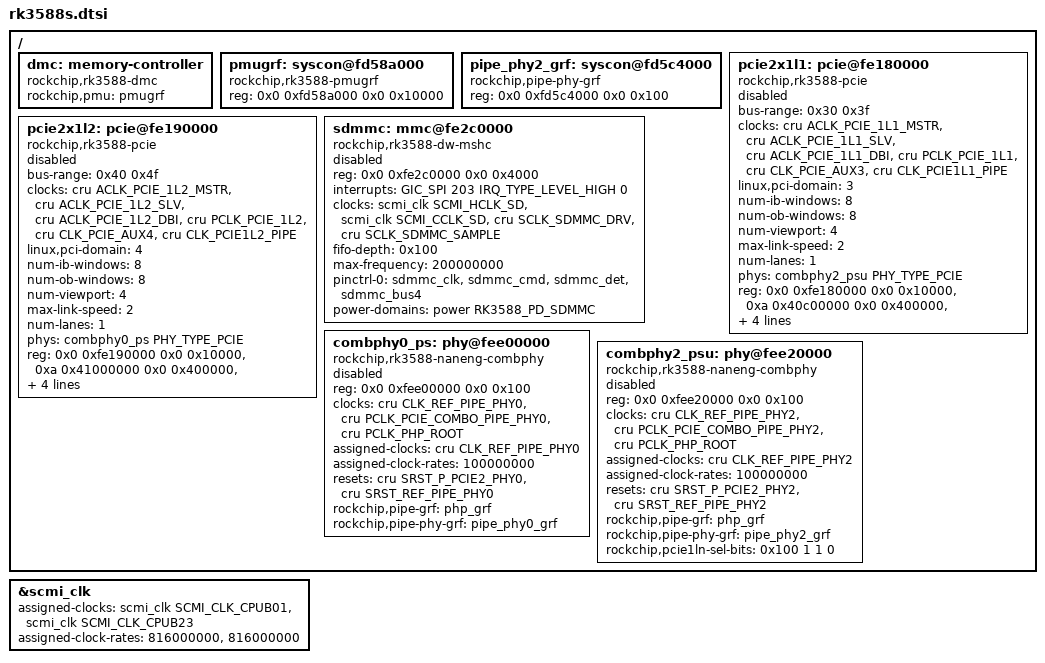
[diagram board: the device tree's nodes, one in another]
/ {
	dmc: memory-controller {
		compatible = "rockchip,rk3588-dmc";
		rockchip,pmu = <&pmugrf>;
	};

	pmugrf: syscon@fd58a000 {
		compatible = "rockchip,rk3588-pmugrf", "syscon", "simple-mfd";
		reg = <0x0 0xfd58a000 0x0 0x10000>;
	};

	pipe_phy2_grf: syscon@fd5c4000 {
		compatible = "rockchip,pipe-phy-grf", "syscon";
		reg = <0x0 0xfd5c4000 0x0 0x100>;
	};

	pcie2x1l1: pcie@fe180000 {
		compatible = "rockchip,rk3588-pcie", "snps,dw-pcie";
		#address-cells = <3>;
		#size-cells = <2>;
		bus-range = <0x30 0x3f>;
		clocks = <&cru ACLK_PCIE_1L1_MSTR>, <&cru ACLK_PCIE_1L1_SLV>,
			 <&cru ACLK_PCIE_1L1_DBI>, <&cru PCLK_PCIE_1L1>,
			 <&cru CLK_PCIE_AUX3>, <&cru CLK_PCIE1L1_PIPE>;
		clock-names = "aclk_mst", "aclk_slv",
			      "aclk_dbi", "pclk",
			      "aux", "pipe";
		device_type = "pci";
		linux,pci-domain = <3>;
		num-ib-windows = <8>;
		num-ob-windows = <8>;
		num-viewport = <4>;
		max-link-speed = <2>;
		num-lanes = <1>;
		phys = <&combphy2_psu PHY_TYPE_PCIE>;
		phy-names = "pcie-phy";
		ranges = <0x81000000 0x0 0xf3100000 0x0 0xf3100000 0x0 0x100000
			  0x82000000 0x0 0xf3200000 0x0 0xf3200000 0x0 0xe00000
			  0xc3000000 0x9 0xc0000000 0x9 0xc0000000 0x0 0x40000000>;
		reg = <0x0 0xfe180000 0x0 0x10000>,
		      <0xa 0x40c00000 0x0 0x400000>,
		      <0x0 0xf3000000 0x0 0x100000>;
		reg-names = "apb", "dbi", "config";
		resets = <&cru SRST_PCIE3_POWER_UP>, <&cru SRST_P_PCIE3>;
		reset-names = "pcie", "periph";
		rockchip,pipe-grf = <&php_grf>;
		status = "disabled";
	};

	pcie2x1l2: pcie@fe190000 {
		compatible = "rockchip,rk3588-pcie", "snps,dw-pcie";
		#address-cells = <3>;
		#size-cells = <2>;
		bus-range = <0x40 0x4f>;
		clocks = <&cru ACLK_PCIE_1L2_MSTR>, <&cru ACLK_PCIE_1L2_SLV>,
			 <&cru ACLK_PCIE_1L2_DBI>, <&cru PCLK_PCIE_1L2>,
			 <&cru CLK_PCIE_AUX4>, <&cru CLK_PCIE1L2_PIPE>;
		clock-names = "aclk_mst", "aclk_slv",
			      "aclk_dbi", "pclk",
			      "aux", "pipe";
		device_type = "pci";
		linux,pci-domain = <4>;
		num-ib-windows = <8>;
		num-ob-windows = <8>;
		num-viewport = <4>;
		max-link-speed = <2>;
		num-lanes = <1>;
		phys = <&combphy0_ps PHY_TYPE_PCIE>;
		phy-names = "pcie-phy";
		ranges = <0x81000000 0x0 0xf4100000 0x0 0xf4100000 0x0 0x100000
			  0x82000000 0x0 0xf4200000 0x0 0xf4200000 0x0 0xe00000
			  0xc3000000 0xa 0x00000000 0xa 0x00000000 0x0 0x40000000>;
		reg = <0x0 0xfe190000 0x0 0x10000>,
		      <0xa 0x41000000 0x0 0x400000>,
		      <0x0 0xf4000000 0x0 0x100000>;
		reg-names = "apb", "dbi", "config";
		resets = <&cru SRST_PCIE4_POWER_UP>, <&cru SRST_P_PCIE4>;
		reset-names = "pcie", "periph";
		rockchip,pipe-grf = <&php_grf>;
		status = "disabled";
	};

	sdmmc: mmc@fe2c0000 {
		compatible = "rockchip,rk3588-dw-mshc", "rockchip,rk3288-dw-mshc";
		reg = <0x0 0xfe2c0000 0x0 0x4000>;
		interrupts = <GIC_SPI 203 IRQ_TYPE_LEVEL_HIGH 0>;
		clocks = <&scmi_clk SCMI_HCLK_SD>, <&scmi_clk SCMI_CCLK_SD>,
			 <&cru SCLK_SDMMC_DRV>, <&cru SCLK_SDMMC_SAMPLE>;
		clock-names = "biu", "ciu", "ciu-drive", "ciu-sample";
		fifo-depth = <0x100>;
		max-frequency = <200000000>;
		pinctrl-names = "default";
		pinctrl-0 = <&sdmmc_clk &sdmmc_cmd &sdmmc_det &sdmmc_bus4>;
		power-domains = <&power RK3588_PD_SDMMC>;
		status = "disabled";
	};

	combphy0_ps: phy@fee00000 {
		compatible = "rockchip,rk3588-naneng-combphy";
		reg = <0x0 0xfee00000 0x0 0x100>;
		#phy-cells = <1>;
		clocks = <&cru CLK_REF_PIPE_PHY0>, <&cru PCLK_PCIE_COMBO_PIPE_PHY0>,
			 <&cru PCLK_PHP_ROOT>;
		clock-names = "refclk", "apbclk", "phpclk";
		assigned-clocks = <&cru CLK_REF_PIPE_PHY0>;
		assigned-clock-rates = <100000000>;
		resets = <&cru SRST_P_PCIE2_PHY0>, <&cru SRST_REF_PIPE_PHY0>;
		reset-names = "combphy-apb", "combphy";
		rockchip,pipe-grf = <&php_grf>;
		rockchip,pipe-phy-grf = <&pipe_phy0_grf>;
		status = "disabled";
	};

	combphy2_psu: phy@fee20000 {
		compatible = "rockchip,rk3588-naneng-combphy";
		reg = <0x0 0xfee20000 0x0 0x100>;
		#phy-cells = <1>;
		clocks = <&cru CLK_REF_PIPE_PHY2>, <&cru PCLK_PCIE_COMBO_PIPE_PHY2>,
			 <&cru PCLK_PHP_ROOT>;
		clock-names = "refclk", "apbclk", "phpclk";
		assigned-clocks = <&cru CLK_REF_PIPE_PHY2>;
		assigned-clock-rates = <100000000>;
		resets = <&cru SRST_P_PCIE2_PHY2>, <&cru SRST_REF_PIPE_PHY2>;
		reset-names = "combphy-apb", "combphy";
		rockchip,pipe-grf = <&php_grf>;
		rockchip,pipe-phy-grf = <&pipe_phy2_grf>;
		rockchip,pcie1ln-sel-bits = <0x100 1 1 0>;
		status = "disabled";
	};
};

&scmi_clk {
	assigned-clocks = <&scmi_clk SCMI_CLK_CPUB01>,
			  <&scmi_clk SCMI_CLK_CPUB23>;
	assigned-clock-rates = <816000000>, <816000000>;
};
